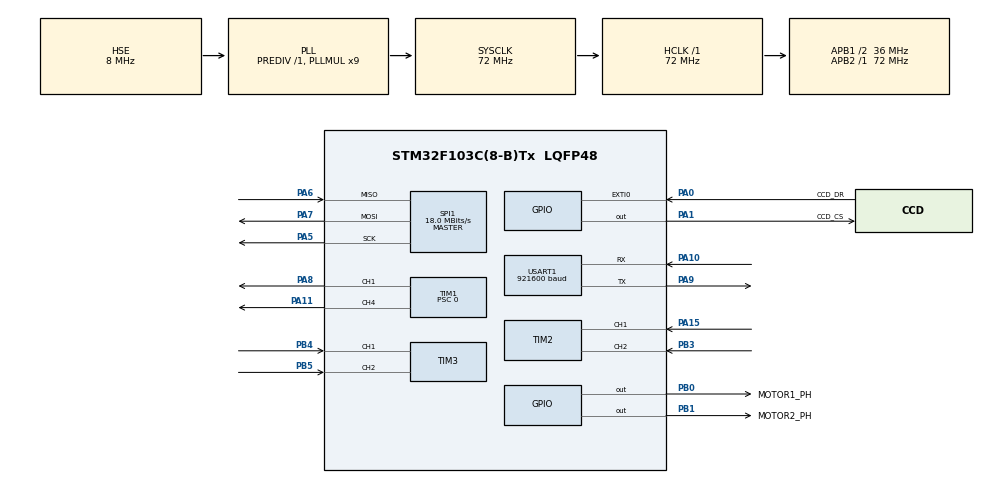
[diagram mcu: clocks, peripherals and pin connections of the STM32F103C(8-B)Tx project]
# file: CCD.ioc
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Dma.Request0=USART1_TX
Dma.USART1_TX.0.Direction=DMA_MEMORY_TO_PERIPH
Dma.USART1_TX.0.Instance=DMA1_Channel4
Dma.USART1_TX.0.MemDataAlignment=DMA_MDATAALIGN_BYTE
Dma.USART1_TX.0.MemInc=DMA_MINC_ENABLE
Dma.USART1_TX.0.Mode=DMA_NORMAL
Dma.USART1_TX.0.PeriphDataAlignment=DMA_PDATAALIGN_BYTE
Dma.USART1_TX.0.PeriphInc=DMA_PINC_DISABLE
Dma.USART1_TX.0.Priority=DMA_PRIORITY_HIGH
Mcu.Family=STM32F1
Mcu.Name=STM32F103C(8-B)Tx
Mcu.Package=LQFP48
NVIC.DMA1_Channel4_IRQn=true\:6\:0\:true\:false\:true\:true\:true\:true
NVIC.EXTI0_IRQn=true\:5\:0\:true\:false\:true\:true\:true\:true
NVIC.PriorityGroup=NVIC_PRIORITYGROUP_4
NVIC.USART1_IRQn=true\:7\:0\:true\:false\:true\:true\:true\:true
PA0-WKUP.GPIO_Label=CCD_DR
PA0-WKUP.GPIO_ModeDefaultEXTI=GPIO_MODE_IT_FALLING
PA0-WKUP.GPIO_PuPd=GPIO_PULLUP
PA0-WKUP.Signal=GPXTI0
PA1.GPIO_Label=CCD_CS
PA1.GPIO_PuPd=GPIO_NOPULL
PA1.PinState=GPIO_PIN_SET
PA1.Signal=GPIO_Output
PA10.Mode=Asynchronous
PA10.Signal=USART1_RX
PA11.Signal=S_TIM1_CH4
PA13.Mode=Serial_Wire
PA13.Signal=SYS_JTMS-SWDIO
PA14.Mode=Serial_Wire
PA14.Signal=SYS_JTCK-SWCLK
PA15.Signal=S_TIM2_CH1_ETR
PA5.Mode=Full_Duplex_Master
PA5.Signal=SPI1_SCK
PA6.Mode=Full_Duplex_Master
PA6.Signal=SPI1_MISO
PA7.Mode=Full_Duplex_Master
PA7.Signal=SPI1_MOSI
PA8.Signal=S_TIM1_CH1
PA9.Mode=Asynchronous
PA9.Signal=USART1_TX
PB0.GPIO_Label=MOTOR1_PH
PB0.Signal=GPIO_Output
PB1.GPIO_Label=MOTOR2_PH
PB1.Signal=GPIO_Output
PB3.Signal=S_TIM2_CH2
PB4.Signal=S_TIM3_CH1
PB5.Signal=S_TIM3_CH2
PD0-OSC_IN.Mode=HSE-External-Oscillator
PD0-OSC_IN.Signal=RCC_OSC_IN
PD1-OSC_OUT.Mode=HSE-External-Oscillator
PD1-OSC_OUT.Signal=RCC_OSC_OUT
ProjectManager.HeapSize=0x200
ProjectManager.StackSize=0x400
ProjectManager.TargetToolchain=MDK-ARM V5.32
RCC.AHBFreq_Value=72000000
RCC.APB1CLKDivider=RCC_HCLK_DIV2
RCC.APB1Freq_Value=36000000
RCC.APB1TimFreq_Value=72000000
RCC.APB2Freq_Value=72000000
RCC.APB2TimFreq_Value=72000000
RCC.HCLKFreq_Value=72000000
RCC.PLLMUL=RCC_PLL_MUL9
RCC.PLLSourceVirtual=RCC_PLLSOURCE_HSE
RCC.SYSCLKFreq_VALUE=72000000
RCC.SYSCLKSource=RCC_SYSCLKSOURCE_PLLCLK
RCC.USBFreq_Value=72000000
SH.S_TIM1_CH1.0=TIM1_CH1,PWM Generation1 CH1
SH.S_TIM1_CH4.0=TIM1_CH4,PWM Generation4 CH4
SH.S_TIM2_CH1_ETR.0=TIM2_CH1,Encoder_Interface
SH.S_TIM2_CH2.0=TIM2_CH2,Encoder_Interface
SH.S_TIM3_CH1.0=TIM3_CH1,Encoder_Interface
SH.S_TIM3_CH2.0=TIM3_CH2,Encoder_Interface
SPI1.BaudRatePrescaler=SPI_BAUDRATEPRESCALER_4
SPI1.CalculateBaudRate=18.0 MBits/s
SPI1.Direction=SPI_DIRECTION_2LINES
SPI1.Mode=SPI_MODE_MASTER
SPI1.VirtualType=VM_MASTER
TIM1.Channel-PWM\ Generation1\ CH1=TIM_CHANNEL_1
TIM1.Channel-PWM\ Generation4\ CH4=TIM_CHANNEL_4
TIM1.Period=3599
TIM1.Prescaler=0
TIM2.EncoderMode=TIM_ENCODERMODE_TI12
TIM2.IC1Filter=6
TIM2.IC2Filter=6
TIM3.EncoderMode=TIM_ENCODERMODE_TI12
TIM3.IC1Filter=6
TIM3.IC2Filter=6
USART1.BaudRate=921600
USART1.VirtualMode=VM_ASYNC
VP_TIM1_VS_ClockSourceINT.Mode=Internal
board=custom

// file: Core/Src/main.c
/* USER CODE BEGIN Header */
// 程序入口只负责时钟、外设和应用初始化；控制逻辑位于 MyCode/Mod/track.c。
/* USER CODE END Header */
#include "main.h"
#include "dma.h"
#include "gpio.h"
#include "spi.h"
#include "tim.h"
#include "usart.h"
/* USER CODE BEGIN Includes */
#include "track.h"
/* USER CODE END Includes */

void SystemClock_Config(void);
static void InitializePeripherals(void);

int main(void)
{
  // 初始化 HAL 和系统时钟，之后才能使用外设与 HAL 时间基准。
  HAL_Init();
  SystemClock_Config();

  // 保持 CubeMX 的外设初始化顺序；DMA 必须先于串口初始化。
  InitializePeripherals();

  /* USER CODE BEGIN 2 */
  // 初始化小车控制与 CCD；识别到有效窄线后自动起步。
  Track_Init();
  /* USER CODE END 2 */

  while (1)
  {
    /* USER CODE BEGIN 3 */
    // Mod 轮询负责采样、循迹和双轮速度控制。
    Track_Poll();
    /* USER CODE END 3 */
  }
}

// 按 CubeMX 配置初始化引脚、DMA 和各外设。
static void InitializePeripherals(void)
{
  MX_GPIO_Init();
  MX_DMA_Init();
  MX_SPI1_Init();
  MX_USART1_UART_Init();
  MX_TIM1_Init();
  MX_TIM2_Init();
  MX_TIM3_Init();
}

// HSE 为 8 MHz，经 PLL 倍频 9 得到 72 MHz 系统时钟。
// AHB 和 APB2 为 72 MHz，APB1 分频 2 后为 36 MHz。
void SystemClock_Config(void)
{
  RCC_OscInitTypeDef oscillator_config = {0};
  RCC_ClkInitTypeDef bus_clock_config = {0};

  // 配置外部晶振和 PLL；保留 CubeMX 启用 HSI 的原始设置。
  oscillator_config.OscillatorType = RCC_OSCILLATORTYPE_HSE;
  oscillator_config.HSEState = RCC_HSE_ON;
  oscillator_config.HSEPredivValue = RCC_HSE_PREDIV_DIV1;
  oscillator_config.HSIState = RCC_HSI_ON;
  oscillator_config.PLL.PLLState = RCC_PLL_ON;
  oscillator_config.PLL.PLLSource = RCC_PLLSOURCE_HSE;
  oscillator_config.PLL.PLLMUL = RCC_PLL_MUL9;

  if (HAL_RCC_OscConfig(&oscillator_config) != HAL_OK)
  {
    Error_Handler();
  }

  // PLL 输出直接供给 CPU；APB1 分频到 36 MHz。
  bus_clock_config.ClockType = RCC_CLOCKTYPE_HCLK | RCC_CLOCKTYPE_SYSCLK |
                                RCC_CLOCKTYPE_PCLK1 | RCC_CLOCKTYPE_PCLK2;
  bus_clock_config.SYSCLKSource = RCC_SYSCLKSOURCE_PLLCLK;
  bus_clock_config.AHBCLKDivider = RCC_SYSCLK_DIV1;
  bus_clock_config.APB1CLKDivider = RCC_HCLK_DIV2;
  bus_clock_config.APB2CLKDivider = RCC_HCLK_DIV1;

  if (HAL_RCC_ClockConfig(&bus_clock_config, FLASH_LATENCY_2) != HAL_OK)
  {
    Error_Handler();
  }
}

// 初始化失败后关闭中断并停留在此处，等待人工复位。
void Error_Handler(void)
{
  __disable_irq();

  while (1)
  {
  }
}
